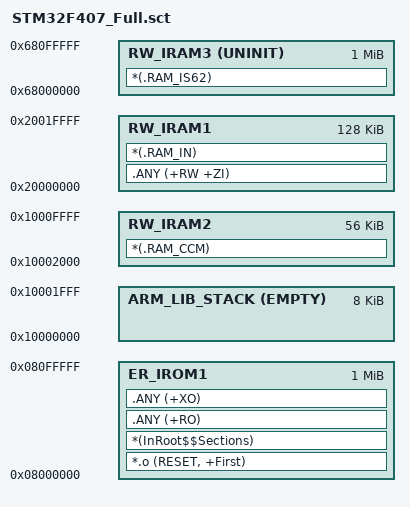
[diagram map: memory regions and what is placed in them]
; *************************************************************
; *** Scatter-Loading Description File generated by uVision ***
; *************************************************************

;flash加载区域
LR_IROM1 0x08000000 0x00100000  {    ; load region size_region
  ;代码执行区域
  ER_IROM1 0x08000000 0x00100000  {  ; load address = execution address
   *.o (RESET, +First)
   *(InRoot$$Sections)
   .ANY (+RO)
   .ANY (+XO)
  }
  ;主RAM空间 128KB
  RW_IRAM1 0x20000000 0x00020000  {  ; RW data
   .ANY (+RW +ZI);变量主要存储在这里
   *(.RAM_IN);指定内存区域名称,可以用于内存管理定义数组
  }
  ;CCM空间 64KB
  RW_IRAM2 0x10002000 0x0000E000  {
   *(.RAM_CCM);指定内存区域名称,可以用于内存管理定义数组
  }
  ;SRAM空间 UNINIT表示不初始化 1MB
  RW_IRAM3 0x68000000 UNINIT 0x00100000  {
   *(.RAM_IS62);指定内存区域名称,可以用于内存管理定义数组
  }
  ;指定系统堆位置
  ;EMPTY：在执行区中保留一个给定长度的空白内存块，通常供堆或堆栈使用
  ;ARM_LIB_HEAP 0x20000000 EMPTY 0x00002000 {}
  ;指定系统栈位置,栈的方向是向下生长的，所以要在栈大小的前面加一个减号（注意那个减号）；属性是EMPTY
  ARM_LIB_STACK 0x10002000 EMPTY -0x00002000 {}
}

